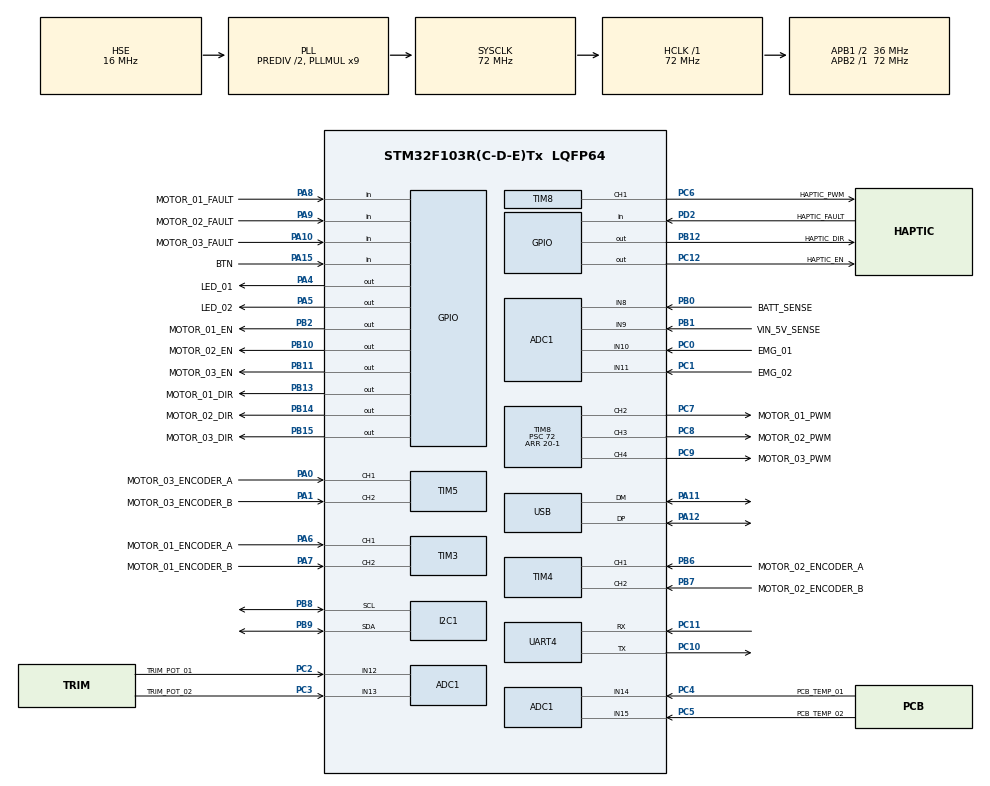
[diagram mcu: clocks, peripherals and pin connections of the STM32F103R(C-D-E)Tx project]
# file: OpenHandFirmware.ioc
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ADC1.Channel-1\#ChannelRegularConversion=ADC_CHANNEL_8
ADC1.NbrOfConversion=1
ADC1.NbrOfConversionFlag=1
ADC1.Rank-1\#ChannelRegularConversion=1
ADC1.SamplingTime-1\#ChannelRegularConversion=ADC_SAMPLETIME_1CYCLE_5
ADC1.master=1
Mcu.Family=STM32F1
Mcu.Name=STM32F103R(C-D-E)Tx
Mcu.Package=LQFP64
NVIC.PriorityGroup=NVIC_PRIORITYGROUP_4
NVIC.TIM6_IRQn=true\:15\:0\:false\:false\:true\:false\:true\:true
NVIC.TimeBase=TIM6_IRQn
NVIC.TimeBaseIP=TIM6
PA0-WKUP.GPIO_Label=MOTOR_03_ENCODER_A
PA0-WKUP.Signal=S_TIM5_CH1
PA1.GPIO_Label=MOTOR_03_ENCODER_B
PA1.Signal=S_TIM5_CH2
PA10.GPIO_Label=MOTOR_03_FAULT
PA10.Signal=GPIO_Input
PA11.Mode=Device
PA11.Signal=USB_DM
PA12.Mode=Device
PA12.Signal=USB_DP
PA13.Mode=Serial_Wire
PA13.Signal=SYS_JTMS-SWDIO
PA14.Mode=Serial_Wire
PA14.Signal=SYS_JTCK-SWCLK
PA15.GPIO_Label=BTN
PA15.Signal=GPIO_Input
PA4.GPIO_Label=LED_01
PA4.Signal=GPIO_Output
PA5.GPIO_Label=LED_02
PA5.Signal=GPIO_Output
PA6.GPIO_Label=MOTOR_01_ENCODER_A
PA6.Signal=S_TIM3_CH1
PA7.GPIO_Label=MOTOR_01_ENCODER_B
PA7.Signal=S_TIM3_CH2
PA8.GPIO_Label=MOTOR_01_FAULT
PA8.Signal=GPIO_Input
PA9.GPIO_Label=MOTOR_02_FAULT
PA9.Signal=GPIO_Input
PB0.GPIO_Label=BATT_SENSE
PB0.Signal=ADCx_IN8
PB1.GPIO_Label=VIN_5V_SENSE
PB1.Signal=ADCx_IN9
PB10.GPIO_Label=MOTOR_02_EN
PB10.Signal=GPIO_Output
PB11.GPIO_Label=MOTOR_03_EN
PB11.Signal=GPIO_Output
PB12.GPIO_Label=HAPTIC_DIR
PB12.Signal=GPIO_Output
PB13.GPIO_Label=MOTOR_01_DIR
PB13.Signal=GPIO_Output
PB14.GPIO_Label=MOTOR_02_DIR
PB14.Signal=GPIO_Output
PB15.GPIO_Label=MOTOR_03_DIR
PB15.Signal=GPIO_Output
PB2.GPIO_Label=MOTOR_01_EN
PB2.Signal=GPIO_Output
PB6.GPIO_Label=MOTOR_02_ENCODER_A
PB6.Signal=S_TIM4_CH1
PB7.GPIO_Label=MOTOR_02_ENCODER_B
PB7.Signal=S_TIM4_CH2
PB8.Mode=I2C
PB8.Signal=I2C1_SCL
PB9.Mode=I2C
PB9.Signal=I2C1_SDA
PC0.GPIO_Label=EMG_01
PC0.Signal=ADCx_IN10
PC1.GPIO_Label=EMG_02
PC1.Signal=ADCx_IN11
PC10.Mode=Asynchronous
PC10.Signal=UART4_TX
PC11.Mode=Asynchronous
PC11.Signal=UART4_RX
PC12.GPIO_Label=HAPTIC_EN
PC12.Signal=GPIO_Output
PC2.GPIO_Label=TRIM_POT_01
PC2.Signal=ADCx_IN12
PC3.GPIO_Label=TRIM_POT_02
PC3.Signal=ADCx_IN13
PC4.GPIO_Label=PCB_TEMP_01
PC4.Signal=ADCx_IN14
PC5.GPIO_Label=PCB_TEMP_02
PC5.Signal=ADCx_IN15
PC6.GPIO_Label=HAPTIC_PWM
PC6.Signal=S_TIM8_CH1
PC7.GPIO_Label=MOTOR_01_PWM
PC7.Signal=S_TIM8_CH2
PC8.GPIO_Label=MOTOR_02_PWM
PC8.Signal=S_TIM8_CH3
PC9.GPIO_Label=MOTOR_03_PWM
PC9.Signal=S_TIM8_CH4
PD0-OSC_IN.Mode=HSE-External-Oscillator
PD0-OSC_IN.Signal=RCC_OSC_IN
PD1-OSC_OUT.Mode=HSE-External-Oscillator
PD1-OSC_OUT.Signal=RCC_OSC_OUT
PD2.GPIO_Label=HAPTIC_FAULT
PD2.Signal=GPIO_Input
ProjectManager.HeapSize=0x200
ProjectManager.StackSize=0x400
ProjectManager.TargetToolchain=STM32CubeIDE
RCC.ADCPresc=RCC_ADCPCLK2_DIV6
RCC.AHBFreq_Value=72000000
RCC.APB1CLKDivider=RCC_HCLK_DIV2
RCC.APB1Freq_Value=36000000
RCC.APB1TimFreq_Value=72000000
RCC.APB2Freq_Value=72000000
RCC.APB2TimFreq_Value=72000000
RCC.HCLKFreq_Value=72000000
RCC.HSEDivPLL=RCC_HSE_PREDIV_DIV2
RCC.HSE_VALUE=16000000
RCC.PLLMUL=RCC_PLL_MUL9
RCC.PLLSourceVirtual=RCC_PLLSOURCE_HSE
RCC.SYSCLKFreq_VALUE=72000000
RCC.SYSCLKSource=RCC_SYSCLKSOURCE_PLLCLK
RCC.USBFreq_Value=48000000
RCC.USBPrescaler=RCC_USBCLKSOURCE_PLL_DIV1_5
SH.ADCx_IN10.0=ADC1_IN10,IN10
SH.ADCx_IN11.0=ADC1_IN11,IN11
SH.ADCx_IN12.0=ADC1_IN12,IN12
SH.ADCx_IN13.0=ADC1_IN13,IN13
SH.ADCx_IN14.0=ADC1_IN14,IN14
SH.ADCx_IN15.0=ADC1_IN15,IN15
SH.ADCx_IN8.0=ADC1_IN8,IN8
SH.ADCx_IN9.0=ADC1_IN9,IN9
SH.S_TIM3_CH1.0=TIM3_CH1,Encoder_Interface
SH.S_TIM3_CH2.0=TIM3_CH2,Encoder_Interface
SH.S_TIM4_CH1.0=TIM4_CH1,Encoder_Interface
SH.S_TIM4_CH2.0=TIM4_CH2,Encoder_Interface
SH.S_TIM5_CH1.0=TIM5_CH1,Encoder_Interface
SH.S_TIM5_CH2.0=TIM5_CH2,Encoder_Interface
SH.S_TIM8_CH1.0=TIM8_CH1,PWM Generation1 CH1
SH.S_TIM8_CH2.0=TIM8_CH2,PWM Generation2 CH2
SH.S_TIM8_CH3.0=TIM8_CH3,Output Compare3 CH3
SH.S_TIM8_CH4.0=TIM8_CH4,PWM Generation4 CH4
TIM8.Channel-Output\ Compare3\ CH3=TIM_CHANNEL_3
TIM8.Channel-PWM\ Generation1\ CH1=TIM_CHANNEL_1
TIM8.Channel-PWM\ Generation2\ CH2=TIM_CHANNEL_2
TIM8.Channel-PWM\ Generation4\ CH4=TIM_CHANNEL_4
TIM8.Period=20-1
TIM8.Prescaler=72
UART4.VirtualMode=Asynchronous
VP_SYS_VS_tim6.Mode=TIM6
board=custom

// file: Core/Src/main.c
/* USER CODE BEGIN Header */
/**
  ******************************************************************************
  * @file           : main.c
  * @brief          : Main program body
  ******************************************************************************
  * @attention
  *
  * Copyright (c) 2025 STMicroelectronics.
  * All rights reserved.
  *
  * This software is licensed under terms that can be found in the LICENSE file
  * in the root directory of this software component.
  * If no LICENSE file comes with this software, it is provided AS-IS.
  *
  ******************************************************************************
  */
/* USER CODE END Header */
#include "main.h"

/* USER CODE BEGIN Includes */
/** @todo Add everything needed to start our 'OS' */

/** Project specific includes */
#include "defines.h"

/** OS includes */
#include "os_e.h"

/** Component includes */
#include "led_e.h"

/* USER CODE END Includes */

ADC_HandleTypeDef hadc1;

I2C_HandleTypeDef hi2c1;

TIM_HandleTypeDef htim3;
TIM_HandleTypeDef htim4;
TIM_HandleTypeDef htim5;
TIM_HandleTypeDef htim8;

UART_HandleTypeDef huart4;

PCD_HandleTypeDef hpcd_USB_FS;

void SystemClock_Config(void);
static void MX_GPIO_Init(void);
static void MX_TIM3_Init(void);
static void MX_TIM4_Init(void);
static void MX_TIM5_Init(void);
static void MX_USB_PCD_Init(void);
static void MX_TIM8_Init(void);
static void MX_ADC1_Init(void);
static void MX_I2C1_Init(void);
static void MX_UART4_Init(void);

int main(void)
{

  /* MCU Configuration--------------------------------------------------------*/

  /* Reset of all peripherals, Initializes the Flash interface and the Systick. */
  HAL_Init();

  /* Configure the system clock */
  SystemClock_Config();

  /* USER CODE BEGIN SysInit */
  /** @todo Add everything needed to init our 'OS' */
  /* Get OS singleton instance */
  os_g_Manager_s* os = os_f_GetManagerInstance_s();

  /* Register drivers with the OS */
  os_f_RegisterComponent_v(os, led_f_GetInstance_s());
  /* USER CODE END SysInit */

  /* Initialize all configured peripherals */
  MX_GPIO_Init();
  MX_TIM3_Init();
  MX_TIM4_Init();
  MX_TIM5_Init();
  MX_USB_PCD_Init();
  MX_TIM8_Init();
  MX_ADC1_Init();
  MX_I2C1_Init();
  MX_UART4_Init();
  /* USER CODE BEGIN 2 */
  /* Initialize all registered drivers */
  os_f_InitializeComponents_v(os);
  /* USER CODE END 2 */

  /* Infinite loop */
  while (1)
  {

    /* USER CODE BEGIN 3 */
    /* Handle all registered drivers */
    os_f_HandleComponents_v(os);
  }
  /* USER CODE END 3 */
}

void SystemClock_Config(void)
{
  RCC_OscInitTypeDef RCC_OscInitStruct = {0};
  RCC_ClkInitTypeDef RCC_ClkInitStruct = {0};
  RCC_PeriphCLKInitTypeDef PeriphClkInit = {0};

  /** Initializes the RCC Oscillators according to the specified parameters
  * in the RCC_OscInitTypeDef structure.
  */
  RCC_OscInitStruct.OscillatorType = RCC_OSCILLATORTYPE_HSE;
  RCC_OscInitStruct.HSEState = RCC_HSE_ON;
  RCC_OscInitStruct.HSEPredivValue = RCC_HSE_PREDIV_DIV2;
  RCC_OscInitStruct.HSIState = RCC_HSI_ON;
  RCC_OscInitStruct.PLL.PLLState = RCC_PLL_ON;
  RCC_OscInitStruct.PLL.PLLSource = RCC_PLLSOURCE_HSE;
  RCC_OscInitStruct.PLL.PLLMUL = RCC_PLL_MUL9;
  if (HAL_RCC_OscConfig(&RCC_OscInitStruct) != HAL_OK)
  {
    Error_Handler();
  }

  /** Initializes the CPU, AHB and APB buses clocks
  */
  RCC_ClkInitStruct.ClockType = RCC_CLOCKTYPE_HCLK|RCC_CLOCKTYPE_SYSCLK
                              |RCC_CLOCKTYPE_PCLK1|RCC_CLOCKTYPE_PCLK2;
  RCC_ClkInitStruct.SYSCLKSource = RCC_SYSCLKSOURCE_PLLCLK;
  RCC_ClkInitStruct.AHBCLKDivider = RCC_SYSCLK_DIV1;
  RCC_ClkInitStruct.APB1CLKDivider = RCC_HCLK_DIV2;
  RCC_ClkInitStruct.APB2CLKDivider = RCC_HCLK_DIV1;

  if (HAL_RCC_ClockConfig(&RCC_ClkInitStruct, FLASH_LATENCY_2) != HAL_OK)
  {
    Error_Handler();
  }
  PeriphClkInit.PeriphClockSelection = RCC_PERIPHCLK_ADC|RCC_PERIPHCLK_USB;
  PeriphClkInit.AdcClockSelection = RCC_ADCPCLK2_DIV6;
  PeriphClkInit.UsbClockSelection = RCC_USBCLKSOURCE_PLL_DIV1_5;
  if (HAL_RCCEx_PeriphCLKConfig(&PeriphClkInit) != HAL_OK)
  {
    Error_Handler();
  }
}

static void MX_ADC1_Init(void)
{

  ADC_ChannelConfTypeDef sConfig = {0};

  /** Common config
  */
  hadc1.Instance = ADC1;
  hadc1.Init.ScanConvMode = ADC_SCAN_DISABLE;
  hadc1.Init.ContinuousConvMode = DISABLE;
  hadc1.Init.DiscontinuousConvMode = DISABLE;
  hadc1.Init.ExternalTrigConv = ADC_SOFTWARE_START;
  hadc1.Init.DataAlign = ADC_DATAALIGN_RIGHT;
  hadc1.Init.NbrOfConversion = 1;
  if (HAL_ADC_Init(&hadc1) != HAL_OK)
  {
    Error_Handler();
  }

  /** Configure Regular Channel
  */
  sConfig.Channel = ADC_CHANNEL_8;
  sConfig.Rank = ADC_REGULAR_RANK_1;
  sConfig.SamplingTime = ADC_SAMPLETIME_1CYCLE_5;
  if (HAL_ADC_ConfigChannel(&hadc1, &sConfig) != HAL_OK)
  {
    Error_Handler();
  }

}

static void MX_I2C1_Init(void)
{

  hi2c1.Instance = I2C1;
  hi2c1.Init.ClockSpeed = 100000;
  hi2c1.Init.DutyCycle = I2C_DUTYCYCLE_2;
  hi2c1.Init.OwnAddress1 = 0;
  hi2c1.Init.AddressingMode = I2C_ADDRESSINGMODE_7BIT;
  hi2c1.Init.DualAddressMode = I2C_DUALADDRESS_DISABLE;
  hi2c1.Init.OwnAddress2 = 0;
  hi2c1.Init.GeneralCallMode = I2C_GENERALCALL_DISABLE;
  hi2c1.Init.NoStretchMode = I2C_NOSTRETCH_DISABLE;
  if (HAL_I2C_Init(&hi2c1) != HAL_OK)
  {
    Error_Handler();
  }

}

static void MX_TIM3_Init(void)
{

  TIM_Encoder_InitTypeDef sConfig = {0};
  TIM_MasterConfigTypeDef sMasterConfig = {0};

  htim3.Instance = TIM3;
  htim3.Init.Prescaler = 0;
  htim3.Init.CounterMode = TIM_COUNTERMODE_UP;
  htim3.Init.Period = 65535;
  htim3.Init.ClockDivision = TIM_CLOCKDIVISION_DIV1;
  htim3.Init.AutoReloadPreload = TIM_AUTORELOAD_PRELOAD_DISABLE;
  sConfig.EncoderMode = TIM_ENCODERMODE_TI1;
  sConfig.IC1Polarity = TIM_ICPOLARITY_RISING;
  sConfig.IC1Selection = TIM_ICSELECTION_DIRECTTI;
  sConfig.IC1Prescaler = TIM_ICPSC_DIV1;
  sConfig.IC1Filter = 0;
  sConfig.IC2Polarity = TIM_ICPOLARITY_RISING;
  sConfig.IC2Selection = TIM_ICSELECTION_DIRECTTI;
  sConfig.IC2Prescaler = TIM_ICPSC_DIV1;
  sConfig.IC2Filter = 0;
  if (HAL_TIM_Encoder_Init(&htim3, &sConfig) != HAL_OK)
  {
    Error_Handler();
  }
  sMasterConfig.MasterOutputTrigger = TIM_TRGO_RESET;
  sMasterConfig.MasterSlaveMode = TIM_MASTERSLAVEMODE_DISABLE;
  if (HAL_TIMEx_MasterConfigSynchronization(&htim3, &sMasterConfig) != HAL_OK)
  {
    Error_Handler();
  }

}

static void MX_TIM4_Init(void)
{

  TIM_Encoder_InitTypeDef sConfig = {0};
  TIM_MasterConfigTypeDef sMasterConfig = {0};

  htim4.Instance = TIM4;
  htim4.Init.Prescaler = 0;
  htim4.Init.CounterMode = TIM_COUNTERMODE_UP;
  htim4.Init.Period = 65535;
  htim4.Init.ClockDivision = TIM_CLOCKDIVISION_DIV1;
  htim4.Init.AutoReloadPreload = TIM_AUTORELOAD_PRELOAD_DISABLE;
  sConfig.EncoderMode = TIM_ENCODERMODE_TI1;
  sConfig.IC1Polarity = TIM_ICPOLARITY_RISING;
  sConfig.IC1Selection = TIM_ICSELECTION_DIRECTTI;
  sConfig.IC1Prescaler = TIM_ICPSC_DIV1;
  sConfig.IC1Filter = 0;
  sConfig.IC2Polarity = TIM_ICPOLARITY_RISING;
  sConfig.IC2Selection = TIM_ICSELECTION_DIRECTTI;
  sConfig.IC2Prescaler = TIM_ICPSC_DIV1;
  sConfig.IC2Filter = 0;
  if (HAL_TIM_Encoder_Init(&htim4, &sConfig) != HAL_OK)
  {
    Error_Handler();
  }
  sMasterConfig.MasterOutputTrigger = TIM_TRGO_RESET;
  sMasterConfig.MasterSlaveMode = TIM_MASTERSLAVEMODE_DISABLE;
  if (HAL_TIMEx_MasterConfigSynchronization(&htim4, &sMasterConfig) != HAL_OK)
  {
    Error_Handler();
  }

}

static void MX_TIM5_Init(void)
{

  TIM_Encoder_InitTypeDef sConfig = {0};
  TIM_MasterConfigTypeDef sMasterConfig = {0};

  htim5.Instance = TIM5;
  htim5.Init.Prescaler = 0;
  htim5.Init.CounterMode = TIM_COUNTERMODE_UP;
  htim5.Init.Period = 65535;
  htim5.Init.ClockDivision = TIM_CLOCKDIVISION_DIV1;
  htim5.Init.AutoReloadPreload = TIM_AUTORELOAD_PRELOAD_DISABLE;
  sConfig.EncoderMode = TIM_ENCODERMODE_TI1;
  sConfig.IC1Polarity = TIM_ICPOLARITY_RISING;
  sConfig.IC1Selection = TIM_ICSELECTION_DIRECTTI;
  sConfig.IC1Prescaler = TIM_ICPSC_DIV1;
  sConfig.IC1Filter = 0;
  sConfig.IC2Polarity = TIM_ICPOLARITY_RISING;
  sConfig.IC2Selection = TIM_ICSELECTION_DIRECTTI;
  sConfig.IC2Prescaler = TIM_ICPSC_DIV1;
  sConfig.IC2Filter = 0;
  if (HAL_TIM_Encoder_Init(&htim5, &sConfig) != HAL_OK)
  {
    Error_Handler();
  }
  sMasterConfig.MasterOutputTrigger = TIM_TRGO_RESET;
  sMasterConfig.MasterSlaveMode = TIM_MASTERSLAVEMODE_DISABLE;
  if (HAL_TIMEx_MasterConfigSynchronization(&htim5, &sMasterConfig) != HAL_OK)
  {
    Error_Handler();
  }

}

static void MX_TIM8_Init(void)
{

  TIM_MasterConfigTypeDef sMasterConfig = {0};
  TIM_OC_InitTypeDef sConfigOC = {0};
  TIM_BreakDeadTimeConfigTypeDef sBreakDeadTimeConfig = {0};

  htim8.Instance = TIM8;
  htim8.Init.Prescaler = 72;
  htim8.Init.CounterMode = TIM_COUNTERMODE_UP;
  htim8.Init.Period = 20-1;
  htim8.Init.ClockDivision = TIM_CLOCKDIVISION_DIV1;
  htim8.Init.RepetitionCounter = 0;
  htim8.Init.AutoReloadPreload = TIM_AUTORELOAD_PRELOAD_DISABLE;
  if (HAL_TIM_PWM_Init(&htim8) != HAL_OK)
  {
    Error_Handler();
  }
  if (HAL_TIM_OC_Init(&htim8) != HAL_OK)
  {
    Error_Handler();
  }
  sMasterConfig.MasterOutputTrigger = TIM_TRGO_RESET;
  sMasterConfig.MasterSlaveMode = TIM_MASTERSLAVEMODE_DISABLE;
  if (HAL_TIMEx_MasterConfigSynchronization(&htim8, &sMasterConfig) != HAL_OK)
  {
    Error_Handler();
  }
  sConfigOC.OCMode = TIM_OCMODE_PWM1;
  sConfigOC.Pulse = 0;
  sConfigOC.OCPolarity = TIM_OCPOLARITY_HIGH;
  sConfigOC.OCNPolarity = TIM_OCNPOLARITY_HIGH;
  sConfigOC.OCFastMode = TIM_OCFAST_DISABLE;
  sConfigOC.OCIdleState = TIM_OCIDLESTATE_RESET;
  sConfigOC.OCNIdleState = TIM_OCNIDLESTATE_RESET;
  if (HAL_TIM_PWM_ConfigChannel(&htim8, &sConfigOC, TIM_CHANNEL_1) != HAL_OK)
  {
    Error_Handler();
  }
  if (HAL_TIM_PWM_ConfigChannel(&htim8, &sConfigOC, TIM_CHANNEL_2) != HAL_OK)
  {
    Error_Handler();
  }
  sConfigOC.OCMode = TIM_OCMODE_TIMING;
  if (HAL_TIM_OC_ConfigChannel(&htim8, &sConfigOC, TIM_CHANNEL_3) != HAL_OK)
  {
    Error_Handler();
  }
  sConfigOC.OCMode = TIM_OCMODE_PWM1;
  if (HAL_TIM_PWM_ConfigChannel(&htim8, &sConfigOC, TIM_CHANNEL_4) != HAL_OK)
  {
    Error_Handler();
  }
  sBreakDeadTimeConfig.OffStateRunMode = TIM_OSSR_DISABLE;
  sBreakDeadTimeConfig.OffStateIDLEMode = TIM_OSSI_DISABLE;
  sBreakDeadTimeConfig.LockLevel = TIM_LOCKLEVEL_OFF;
  sBreakDeadTimeConfig.DeadTime = 0;
  sBreakDeadTimeConfig.BreakState = TIM_BREAK_DISABLE;
  sBreakDeadTimeConfig.BreakPolarity = TIM_BREAKPOLARITY_HIGH;
  sBreakDeadTimeConfig.AutomaticOutput = TIM_AUTOMATICOUTPUT_DISABLE;
  if (HAL_TIMEx_ConfigBreakDeadTime(&htim8, &sBreakDeadTimeConfig) != HAL_OK)
  {
    Error_Handler();
  }
  HAL_TIM_MspPostInit(&htim8);

}

static void MX_UART4_Init(void)
{

  huart4.Instance = UART4;
  huart4.Init.BaudRate = 115200;
  huart4.Init.WordLength = UART_WORDLENGTH_8B;
  huart4.Init.StopBits = UART_STOPBITS_1;
  huart4.Init.Parity = UART_PARITY_NONE;
  huart4.Init.Mode = UART_MODE_TX_RX;
  huart4.Init.HwFlowCtl = UART_HWCONTROL_NONE;
  huart4.Init.OverSampling = UART_OVERSAMPLING_16;
  if (HAL_UART_Init(&huart4) != HAL_OK)
  {
    Error_Handler();
  }

}

static void MX_USB_PCD_Init(void)
{

  hpcd_USB_FS.Instance = USB;
  hpcd_USB_FS.Init.dev_endpoints = 8;
  hpcd_USB_FS.Init.speed = PCD_SPEED_FULL;
  hpcd_USB_FS.Init.low_power_enable = DISABLE;
  hpcd_USB_FS.Init.lpm_enable = DISABLE;
  hpcd_USB_FS.Init.battery_charging_enable = DISABLE;
  if (HAL_PCD_Init(&hpcd_USB_FS) != HAL_OK)
  {
    Error_Handler();
  }

}

static void MX_GPIO_Init(void)
{
  GPIO_InitTypeDef GPIO_InitStruct = {0};

  /* GPIO Ports Clock Enable */
  __HAL_RCC_GPIOD_CLK_ENABLE();
  __HAL_RCC_GPIOC_CLK_ENABLE();
  __HAL_RCC_GPIOA_CLK_ENABLE();
  __HAL_RCC_GPIOB_CLK_ENABLE();

  /*Configure GPIO pin Output Level */
  HAL_GPIO_WritePin(GPIOA, LED_01_Pin|LED_02_Pin, GPIO_PIN_RESET);

  /*Configure GPIO pin Output Level */
  HAL_GPIO_WritePin(GPIOB, MOTOR_01_EN_Pin|MOTOR_02_EN_Pin|MOTOR_03_EN_Pin|HAPTIC_DIR_Pin
                          |MOTOR_01_DIR_Pin|MOTOR_02_DIR_Pin|MOTOR_03_DIR_Pin, GPIO_PIN_RESET);

  /*Configure GPIO pin Output Level */
  HAL_GPIO_WritePin(HAPTIC_EN_GPIO_Port, HAPTIC_EN_Pin, GPIO_PIN_RESET);

  /*Configure GPIO pins : LED_01_Pin LED_02_Pin */
  GPIO_InitStruct.Pin = LED_01_Pin|LED_02_Pin;
  GPIO_InitStruct.Mode = GPIO_MODE_OUTPUT_PP;
  GPIO_InitStruct.Pull = GPIO_NOPULL;
  GPIO_InitStruct.Speed = GPIO_SPEED_FREQ_LOW;
  HAL_GPIO_Init(GPIOA, &GPIO_InitStruct);

  /*Configure GPIO pins : MOTOR_01_EN_Pin MOTOR_02_EN_Pin MOTOR_03_EN_Pin HAPTIC_DIR_Pin
                           MOTOR_01_DIR_Pin MOTOR_02_DIR_Pin MOTOR_03_DIR_Pin */
  GPIO_InitStruct.Pin = MOTOR_01_EN_Pin|MOTOR_02_EN_Pin|MOTOR_03_EN_Pin|HAPTIC_DIR_Pin
                          |MOTOR_01_DIR_Pin|MOTOR_02_DIR_Pin|MOTOR_03_DIR_Pin;
  GPIO_InitStruct.Mode = GPIO_MODE_OUTPUT_PP;
  GPIO_InitStruct.Pull = GPIO_NOPULL;
  GPIO_InitStruct.Speed = GPIO_SPEED_FREQ_LOW;
  HAL_GPIO_Init(GPIOB, &GPIO_InitStruct);

  /*Configure GPIO pins : MOTOR_01_FAULT_Pin MOTOR_02_FAULT_Pin MOTOR_03_FAULT_Pin BTN_Pin */
  GPIO_InitStruct.Pin = MOTOR_01_FAULT_Pin|MOTOR_02_FAULT_Pin|MOTOR_03_FAULT_Pin|BTN_Pin;
  GPIO_InitStruct.Mode = GPIO_MODE_INPUT;
  GPIO_InitStruct.Pull = GPIO_NOPULL;
  HAL_GPIO_Init(GPIOA, &GPIO_InitStruct);

  /*Configure GPIO pin : HAPTIC_EN_Pin */
  GPIO_InitStruct.Pin = HAPTIC_EN_Pin;
  GPIO_InitStruct.Mode = GPIO_MODE_OUTPUT_PP;
  GPIO_InitStruct.Pull = GPIO_NOPULL;
  GPIO_InitStruct.Speed = GPIO_SPEED_FREQ_LOW;
  HAL_GPIO_Init(HAPTIC_EN_GPIO_Port, &GPIO_InitStruct);

  /*Configure GPIO pin : HAPTIC_FAULT_Pin */
  GPIO_InitStruct.Pin = HAPTIC_FAULT_Pin;
  GPIO_InitStruct.Mode = GPIO_MODE_INPUT;
  GPIO_InitStruct.Pull = GPIO_NOPULL;
  HAL_GPIO_Init(HAPTIC_FAULT_GPIO_Port, &GPIO_InitStruct);

}

void HAL_TIM_PeriodElapsedCallback(TIM_HandleTypeDef *htim)
{
  if (htim->Instance == TIM6) {
    HAL_IncTick();
  }
}

void Error_Handler(void)
{
  __disable_irq();
  while (1)
  {
  }
}
